# MCU_NAVSS0_UDMASS_INTA0_CFG_MCAST register map
Vendor: Texas Instruments
Peripheral module from a debugger description file (folder am65x).
Registers are 64-bit, read-write, reset 0xFFFF0000FFFF unless marked. A register's access mark holds for its fields unless they carry their own. Offsets are as the file gives them; lines under a group give offsets from that group; [hi:lo] are bit positions; {n}, {i} and the like mark numbered series; 'fields as' and 'values as' point back to an identical list; <NAME> marks a mode.

## MCU_NAVSS0_UDMASS_INTA0_CFG_MCAST
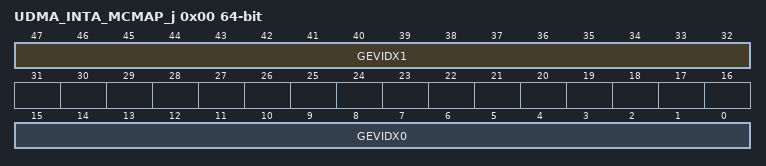
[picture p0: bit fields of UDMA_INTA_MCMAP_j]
0x00 UDMA_INTA_MCMAP_j — This register determines how ingress global events from the ingress global event ETL are written out to the two egress global event ETL intefaces. The index of each of the two egress events is stored in this register, which is selected based in the ingress event index value. Offset = 0h + (j * 20h); where j = 0h to 1FFh for NAVSS0_UDMASS_INTA0_CFG_MCAST j = 0h to 7Fh for MCU_NAVSS0_UDMASS_INTA0_CFG_MCAST
  [47:32] GEVIDX1 — Global event index 1. This field specifies the index of the outgoing global event on ETL 1. Set to 0xFFFF to disable.
  [15:0] GEVIDX0 — Global event index 0. This field specifies the index of the outgoing global event on ETL 0. Set to 0xFFFF to disable.
